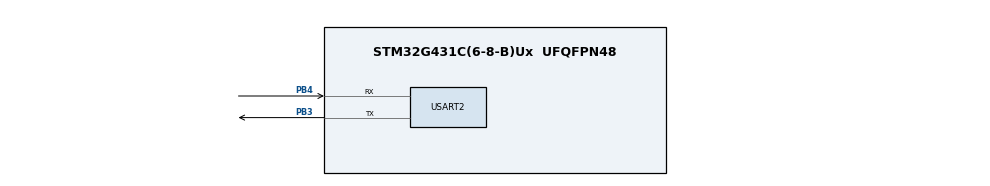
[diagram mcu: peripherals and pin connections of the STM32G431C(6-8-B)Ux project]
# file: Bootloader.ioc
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CRC.CRCLength=CRC_POLYLENGTH_16B
CRC.DefaultInitValueUse=DEFAULT_INIT_VALUE_DISABLE
CRC.DefaultPolynomialUse=DEFAULT_POLYNOMIAL_DISABLE
CRC.GeneratingPolynomial=X12+X5+X0
Mcu.Family=STM32G4
Mcu.Name=STM32G431C(6-8-B)Ux
Mcu.Package=UFQFPN48
NVIC.PriorityGroup=NVIC_PRIORITYGROUP_4
PA13.Mode=Serial_Wire
PA13.Signal=SYS_JTMS-SWDIO
PA14.Mode=Serial_Wire
PA14.Signal=SYS_JTCK-SWCLK
PB3.Mode=Asynchronous
PB3.Signal=USART2_TX
PB4.Mode=Asynchronous
PB4.Signal=USART2_RX
ProjectManager.HeapSize=0x200
ProjectManager.StackSize=0x400
ProjectManager.TargetToolchain=STM32CubeIDE
RCC.AHBFreq_Value=16000000
RCC.APB1Freq_Value=16000000
RCC.APB1TimFreq_Value=16000000
RCC.APB2Freq_Value=16000000
RCC.APB2TimFreq_Value=16000000
RCC.CortexFreq_Value=16000000
RCC.EXTERNAL_CLOCK_VALUE=12288000
RCC.HCLKFreq_Value=16000000
RCC.HSE_VALUE=8000000
RCC.HSI48_VALUE=48000000
RCC.HSI_VALUE=16000000
RCC.LSE_VALUE=32768
RCC.SYSCLKFreq_VALUE=16000000
RCC.USBFreq_Value=64000000
RCC.VCOOutputFreq_Value=128000000
USART2.VirtualMode-Asynchronous=VM_ASYNC
VP_CRC_VS_CRC.Mode=CRC_Activate
VP_SYS_VS_DBSignals.Mode=DisableDeadBatterySignals
board=custom

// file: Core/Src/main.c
/* USER CODE BEGIN Header */
/**
  ******************************************************************************
  * @file           : main.c
  * @brief          : Main program body
  ******************************************************************************
  * @attention
  *
  * Copyright (c) 2024 STMicroelectronics.
  * All rights reserved.
  *
  * This software is licensed under terms that can be found in the LICENSE file
  * in the root directory of this software component.
  * If no LICENSE file comes with this software, it is provided AS-IS.
  *
  ******************************************************************************
  */
/* USER CODE END Header */
#include "main.h"

CRC_HandleTypeDef hcrc;

UART_HandleTypeDef huart2;

void SystemClock_Config(void);
static void MX_GPIO_Init(void);

int main(void)
{

  /* MCU Configuration--------------------------------------------------------*/

  /* Reset of all peripherals, Initializes the Flash interface and the Systick. */
  HAL_Init();

  /* Configure the system clock */
  SystemClock_Config();

  /* Initialize all configured peripherals */
  MX_GPIO_Init();
  MX_CRC_Init();
  MX_USART2_UART_Init();
  /* USER CODE BEGIN 2 */
  tsk_main(NULL);
  /* USER CODE END 2 */

  /* Infinite loop */
  while (1)
  {

  }
}

void SystemClock_Config(void)
{
  LL_FLASH_SetLatency(LL_FLASH_LATENCY_0);
  while(LL_FLASH_GetLatency() != LL_FLASH_LATENCY_0)
  {
  }
  LL_PWR_SetRegulVoltageScaling(LL_PWR_REGU_VOLTAGE_SCALE1);
  LL_RCC_HSI_Enable();
   /* Wait till HSI is ready */
  while(LL_RCC_HSI_IsReady() != 1)
  {
  }

  LL_RCC_HSI_SetCalibTrimming(64);
  LL_RCC_SetSysClkSource(LL_RCC_SYS_CLKSOURCE_HSI);
   /* Wait till System clock is ready */
  while(LL_RCC_GetSysClkSource() != LL_RCC_SYS_CLKSOURCE_STATUS_HSI)
  {
  }

  /* Set AHB prescaler*/
  LL_RCC_SetAHBPrescaler(LL_RCC_SYSCLK_DIV_1);
  LL_RCC_SetAPB1Prescaler(LL_RCC_APB1_DIV_1);
  LL_RCC_SetAPB2Prescaler(LL_RCC_APB2_DIV_1);
  LL_SetSystemCoreClock(16000000);

   /* Update the time base */
  if (HAL_InitTick (TICK_INT_PRIORITY) != HAL_OK)
  {
    Error_Handler();
  }
}

void MX_CRC_Init(void)
{

  hcrc.Instance = CRC;
  hcrc.Init.DefaultPolynomialUse = DEFAULT_POLYNOMIAL_DISABLE;
  hcrc.Init.DefaultInitValueUse = DEFAULT_INIT_VALUE_DISABLE;
  hcrc.Init.GeneratingPolynomial = 4129;
  hcrc.Init.CRCLength = CRC_POLYLENGTH_16B;
  hcrc.Init.InitValue = 0;
  hcrc.Init.InputDataInversionMode = CRC_INPUTDATA_INVERSION_NONE;
  hcrc.Init.OutputDataInversionMode = CRC_OUTPUTDATA_INVERSION_DISABLE;
  hcrc.InputDataFormat = CRC_INPUTDATA_FORMAT_BYTES;
  if (HAL_CRC_Init(&hcrc) != HAL_OK)
  {
    Error_Handler();
  }

}

void MX_USART2_UART_Init(void)
{

  huart2.Instance = USART2;
  huart2.Init.BaudRate = 115200;
  huart2.Init.WordLength = UART_WORDLENGTH_8B;
  huart2.Init.StopBits = UART_STOPBITS_1;
  huart2.Init.Parity = UART_PARITY_NONE;
  huart2.Init.Mode = UART_MODE_TX_RX;
  huart2.Init.HwFlowCtl = UART_HWCONTROL_NONE;
  huart2.Init.OverSampling = UART_OVERSAMPLING_16;
  huart2.Init.OneBitSampling = UART_ONE_BIT_SAMPLE_DISABLE;
  huart2.Init.ClockPrescaler = UART_PRESCALER_DIV1;
  huart2.AdvancedInit.AdvFeatureInit = UART_ADVFEATURE_NO_INIT;
  if (HAL_UART_Init(&huart2) != HAL_OK)
  {
    Error_Handler();
  }
  if (HAL_UARTEx_SetTxFifoThreshold(&huart2, UART_TXFIFO_THRESHOLD_1_8) != HAL_OK)
  {
    Error_Handler();
  }
  if (HAL_UARTEx_SetRxFifoThreshold(&huart2, UART_RXFIFO_THRESHOLD_1_8) != HAL_OK)
  {
    Error_Handler();
  }
  if (HAL_UARTEx_DisableFifoMode(&huart2) != HAL_OK)
  {
    Error_Handler();
  }

}

static void MX_GPIO_Init(void)
{
  GPIO_InitTypeDef GPIO_InitStruct = {0};

  /* GPIO Ports Clock Enable */
  __HAL_RCC_GPIOC_CLK_ENABLE();
  __HAL_RCC_GPIOF_CLK_ENABLE();
  __HAL_RCC_GPIOG_CLK_ENABLE();
  __HAL_RCC_GPIOA_CLK_ENABLE();
  __HAL_RCC_GPIOB_CLK_ENABLE();

  /*Configure GPIO pins : PC13 PC14 PC15 PC4
                           PC6 PC10 PC11 */
  GPIO_InitStruct.Pin = GPIO_PIN_13|GPIO_PIN_14|GPIO_PIN_15|GPIO_PIN_4
                          |GPIO_PIN_6|GPIO_PIN_10|GPIO_PIN_11;
  GPIO_InitStruct.Mode = GPIO_MODE_ANALOG;
  GPIO_InitStruct.Pull = GPIO_NOPULL;
  HAL_GPIO_Init(GPIOC, &GPIO_InitStruct);

  /*Configure GPIO pins : PF0 PF1 */
  GPIO_InitStruct.Pin = GPIO_PIN_0|GPIO_PIN_1;
  GPIO_InitStruct.Mode = GPIO_MODE_ANALOG;
  GPIO_InitStruct.Pull = GPIO_NOPULL;
  HAL_GPIO_Init(GPIOF, &GPIO_InitStruct);

  /*Configure GPIO pin : PG10 */
  GPIO_InitStruct.Pin = GPIO_PIN_10;
  GPIO_InitStruct.Mode = GPIO_MODE_ANALOG;
  GPIO_InitStruct.Pull = GPIO_NOPULL;
  HAL_GPIO_Init(GPIOG, &GPIO_InitStruct);

  /*Configure GPIO pins : PA0 PA1 PA2 PA3
                           PA4 PA5 PA6 PA7
                           PA8 PA9 PA10 PA11
                           PA12 PA15 */
  GPIO_InitStruct.Pin = GPIO_PIN_0|GPIO_PIN_1|GPIO_PIN_2|GPIO_PIN_3
                          |GPIO_PIN_4|GPIO_PIN_5|GPIO_PIN_6|GPIO_PIN_7
                          |GPIO_PIN_8|GPIO_PIN_9|GPIO_PIN_10|GPIO_PIN_11
                          |GPIO_PIN_12|GPIO_PIN_15;
  GPIO_InitStruct.Mode = GPIO_MODE_ANALOG;
  GPIO_InitStruct.Pull = GPIO_NOPULL;
  HAL_GPIO_Init(GPIOA, &GPIO_InitStruct);

  /*Configure GPIO pins : PB0 PB1 PB2 PB10
                           PB11 PB12 PB13 PB14
                           PB15 PB5 PB6 PB7
                           PB8 PB9 */
  GPIO_InitStruct.Pin = GPIO_PIN_0|GPIO_PIN_1|GPIO_PIN_2|GPIO_PIN_10
                          |GPIO_PIN_11|GPIO_PIN_12|GPIO_PIN_13|GPIO_PIN_14
                          |GPIO_PIN_15|GPIO_PIN_5|GPIO_PIN_6|GPIO_PIN_7
                          |GPIO_PIN_8|GPIO_PIN_9;
  GPIO_InitStruct.Mode = GPIO_MODE_ANALOG;
  GPIO_InitStruct.Pull = GPIO_NOPULL;
  HAL_GPIO_Init(GPIOB, &GPIO_InitStruct);

}

void Error_Handler(void)
{
  __disable_irq();
  while (1)
  {
  }
}
